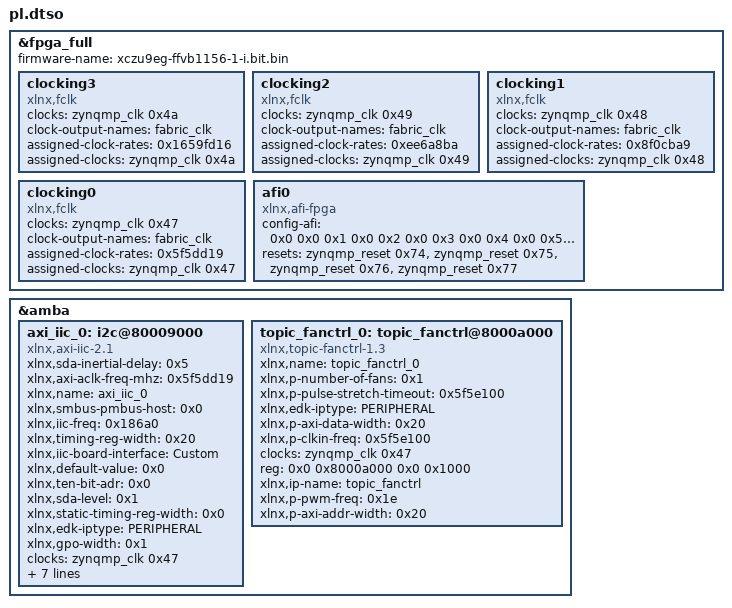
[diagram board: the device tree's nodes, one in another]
/dts-v1/;
/plugin/;

&fpga_full {
        firmware-name = "xczu9eg-ffvb1156-1-i.bit.bin";

        clocking3: clocking3 {
                clocks = <&zynqmp_clk 0x4a>;
                clock-output-names = "fabric_clk";
                #clock-cells = <0x0>;
                assigned-clock-rates = <0x1659fd16>;
                assigned-clocks = <&zynqmp_clk 0x4a>;
                compatible = "xlnx,fclk";
        };

        clocking2: clocking2 {
                clocks = <&zynqmp_clk 0x49>;
                clock-output-names = "fabric_clk";
                #clock-cells = <0x0>;
                assigned-clock-rates = <0xee6a8ba>;
                assigned-clocks = <&zynqmp_clk 0x49>;
                compatible = "xlnx,fclk";
        };

        clocking1: clocking1 {
                clocks = <&zynqmp_clk 0x48>;
                clock-output-names = "fabric_clk";
                #clock-cells = <0x0>;
                assigned-clock-rates = <0x8f0cba9>;
                assigned-clocks = <&zynqmp_clk 0x48>;
                compatible = "xlnx,fclk";
        };

        clocking0: clocking0 {
                clocks = <&zynqmp_clk 0x47>;
                clock-output-names = "fabric_clk";
                #clock-cells = <0x0>;
                assigned-clock-rates = <0x5f5dd19>;
                assigned-clocks = <&zynqmp_clk 0x47>;
                compatible = "xlnx,fclk";
        };

        afi0: afi0 {
                config-afi = <0x0 0x0 0x1 0x0 0x2 0x0 0x3 0x0 0x4 0x0 0x5 0x0 0x6 0x0 0x7 0x0 0x8 0x0 0x9 0x0 0xa 0x0 0xb 0x0 0xc 0x0 0xd 0x0 0xe 0xa00 0xf 0x0>;
                resets = <&zynqmp_reset 0x74>,
                 <&zynqmp_reset 0x75>,
                 <&zynqmp_reset 0x76>,
                 <&zynqmp_reset 0x77>;
                compatible = "xlnx,afi-fpga";
        };
};

&amba {

        axi_iic_0: i2c@80009000 {
                xlnx,sda-inertial-delay = <0x5>;
                xlnx,axi-aclk-freq-mhz = <0x5f5dd19>;
                xlnx,name = "axi_iic_0";
                xlnx,smbus-pmbus-host = <0x0>;
                xlnx,iic-freq = <0x186a0>;
                xlnx,timing-reg-width = <0x20>;
                xlnx,iic-board-interface = "Custom";
                interrupt-names = "iic2intc_irpt";
                xlnx,default-value = <0x0>;
                xlnx,ten-bit-adr = <0x0>;
                clock-names = "s_axi_aclk";
                xlnx,sda-level = <0x1>;
                xlnx,static-timing-reg-width = <0x0>;
                xlnx,edk-iptype = "PERIPHERAL";
                xlnx,gpo-width = <0x1>;
                clocks = <&zynqmp_clk 0x47>;
                reg = <0x0 0x80009000 0x0 0x1000>;
                xlnx,disable-setup-violation-check = <0x0>;
                xlnx,ip-name = "axi_iic";
                interrupt-parent = <&gic>;
                xlnx,scl-inertial-delay = <0x5>;
                compatible = "xlnx,axi-iic-2.1", "xlnx,xps-iic-2.00.a";
                xlnx,iic-freq-khz = <0x64>;
                interrupts = <0x0 0x59 0x4>;
        };

        topic_fanctrl_0: topic_fanctrl@8000a000 {
                xlnx,name = "topic_fanctrl_0";
                clock-names = "S_AXI_ACLK";
                xlnx,p-number-of-fans = <0x1>;
                xlnx,p-pulse-stretch-timeout = <0x5f5e100>;
                xlnx,edk-iptype = "PERIPHERAL";
                xlnx,p-axi-data-width = <0x20>;
                xlnx,p-clkin-freq = <0x5f5e100>;
                clocks = <&zynqmp_clk 0x47>;
                reg = <0x0 0x8000a000 0x0 0x1000>;
                xlnx,ip-name = "topic_fanctrl";
                xlnx,p-pwm-freq = <0x1e>;
                xlnx,p-axi-addr-width = <0x20>;
                compatible = "xlnx,topic-fanctrl-1.3";
        };
};

